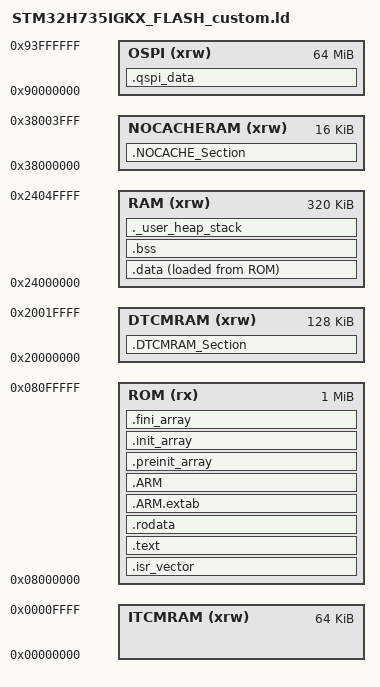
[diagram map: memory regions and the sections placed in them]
/**
 ******************************************************************************
 * @file      LinkerScript.ld
 * @author    Auto-generated by STM32CubeIDE
 *  Abstract    : Linker script for STM32H735G-DK Board embedding STM32H735IGKx Device from stm32h7 series
 *                      1024Kbytes ROM
 *                      64Kbytes ITCMRAM
 *                      320Kbytes RAM
 *
 *            Set heap size, stack size and stack location according
 *            to application requirements.
 *
 *            Set memory bank area and size if external memory is used
 ******************************************************************************
 * @attention
 *
 * <h2><center>&copy; Copyright (c) 2020 STMicroelectronics.
 * All rights reserved.</center></h2>
 *
 * This software component is licensed by ST under BSD 3-Clause license,
 * the "License"; You may not use this file except in compliance with the
 * License. You may obtain a copy of the License at:
 *                        opensource.org/licenses/BSD-3-Clause
 *
 ******************************************************************************
 */

/* Entry Point */
ENTRY(Reset_Handler)

/* Highest address of the user mode stack */
_estack = ORIGIN(RAM) + LENGTH(RAM);	/* end of "RAM" Ram type memory */

_Min_Heap_Size = 0x200 ;	/* required amount of heap  */
_Min_Stack_Size = 0x400 ;	/* required amount of stack */

/* Memories definition */
MEMORY
{
  ITCMRAM    (xrw)    : ORIGIN = 0x00000000,   LENGTH = 64K
  RAM    (xrw)    : ORIGIN = 0x24000000,   LENGTH = 320K
  ROM (rx)      : ORIGIN = 0x08000000, LENGTH = 1024K
   /* RAM_D3 (xrw)    : ORIGIN = 0x38000000,   LENGTH = 16K*/
  DTCMRAM (xrw)      : ORIGIN = 0x20000000, LENGTH = 128K
  NOCACHERAM (xrw)      : ORIGIN = 0x38000000, LENGTH = 16K
  OSPI (xrw)      : ORIGIN = 0x90000000, LENGTH = 65536K
}

/* Sections */
SECTIONS
{
  /* The startup code into "ROM" Rom type memory */
  .isr_vector :
  {
    . = ALIGN(4);
    KEEP(*(.isr_vector)) /* Startup code */
    . = ALIGN(4);
  } >ROM

  /* section to put in the QSPI */
  .qspi_data :
  {
  	. = ALIGN(4);
  	*(.qspi_data)
  	*(.qspi_data*)
  	. = ALIGN(4);
  } >OSPI
  
/*  .audio_files :
  {
  	. = ALIGN(4);
  	*(.audio_files)
  	*(.audio_files*)
  	. = ALIGN(4);
  } >OSPI
*/
  /* The program code and other data into "ROM" Rom type memory */
  .text :
  {
    . = ALIGN(4);
    *(.text)           /* .text sections (code) */
    *(.text*)          /* .text* sections (code) */
    *(.glue_7)         /* glue arm to thumb code */
    *(.glue_7t)        /* glue thumb to arm code */
    *(.eh_frame)

    KEEP (*(.init))
    KEEP (*(.fini))

    . = ALIGN(4);
    _etext = .;        /* define a global symbols at end of code */
  } >ROM

  /* Constant data into "ROM" Rom type memory */
  .rodata :
  {
    . = ALIGN(4);
    *(.rodata)         /* .rodata sections (constants, strings, etc.) */
    *(.rodata*)        /* .rodata* sections (constants, strings, etc.) */
    . = ALIGN(4);
  } >ROM

  .ARM.extab   : { 
    . = ALIGN(4);
    *(.ARM.extab* .gnu.linkonce.armextab.*)
    . = ALIGN(4);
  } >ROM
  
  .ARM : {
    . = ALIGN(4);
    __exidx_start = .;
    *(.ARM.exidx*)
    __exidx_end = .;
    . = ALIGN(4);
  } >ROM

  .preinit_array     :
  {
    . = ALIGN(4);
    PROVIDE_HIDDEN (__preinit_array_start = .);
    KEEP (*(.preinit_array*))
    PROVIDE_HIDDEN (__preinit_array_end = .);
    . = ALIGN(4);
  } >ROM
  
  .init_array :
  {
    . = ALIGN(4);
    PROVIDE_HIDDEN (__init_array_start = .);
    KEEP (*(SORT(.init_array.*)))
    KEEP (*(.init_array*))
    PROVIDE_HIDDEN (__init_array_end = .);
    . = ALIGN(4);
  } >ROM
  
  .fini_array :
  {
    . = ALIGN(4);
    PROVIDE_HIDDEN (__fini_array_start = .);
    KEEP (*(SORT(.fini_array.*)))
    KEEP (*(.fini_array*))
    PROVIDE_HIDDEN (__fini_array_end = .);
    . = ALIGN(4);
  } >ROM

  /* Used by the startup to initialize data */
  _sidata = LOADADDR(.data);

  /* Initialized data sections into "RAM" Ram type memory */
  .data : 
  {
    . = ALIGN(4);
    _sdata = .;        /* create a global symbol at data start */
    *(.data)           /* .data sections */
    *(.data*)          /* .data* sections */

    . = ALIGN(4);
    _edata = .;        /* define a global symbol at data end */
    
  } >RAM AT> ROM

  /* Uninitialized data section into "RAM" Ram type memory */
  . = ALIGN(4);
  .bss :
  {
    /* This is used by the startup in order to initialize the .bss section */
    _sbss = .;         /* define a global symbol at bss start */
    __bss_start__ = _sbss;
    *(.bss)
    *(.bss*)
    *(COMMON)

    . = ALIGN(4);
    _ebss = .;         /* define a global symbol at bss end */
    __bss_end__ = _ebss;
  } >RAM
 

  
  /* used by the startup to initialize data */
 /* _siRAM_D3 = LOADADDR(.RAM_D3);

  .RAM_D3 : {
  . = ALIGN(4);
  _sRAM_D3 = .;        
    . = ALIGN(4);
   _eRAM_D3 = .;        
   } >RAM_D3 */

  /* User_heap_stack section, used to check that there is enough "RAM" Ram  type memory left */
  ._user_heap_stack :
  {
    . = ALIGN(8);
    PROVIDE ( end = . );
    PROVIDE ( _end = . );
    . = . + _Min_Heap_Size;
    . = . + _Min_Stack_Size;
    . = ALIGN(8);
  } >RAM


  _sdtcmram = LOADADDR(.DTCMRAM_Section);
  
  .DTCMRAM_Section :
  {
    . = ALIGN(4);
    _sdtcmram = .;
    *(.DTCMRAM_Section)
    *(.DTCMRAM_Section*)

    . = ALIGN(4);
    _edtcmram = .;
  } >DTCMRAM

  _snocacheram = LOADADDR(.NOCACHE_Section);

  .NOCACHE_Section :
  {
    . = ALIGN(4);
    _snocacheram = .;
    *(.NOCACHE_Section)
    *(.NOCACHE_Section*)

    . = ALIGN(4);
    _enocacheram = .;
  } >NOCACHERAM

  /* Remove information from the compiler libraries */
  /DISCARD/ :
  {
    libc.a ( * )
    libm.a ( * )
    libgcc.a ( * )
  }

  .ARM.attributes 0 : { *(.ARM.attributes) }
}
